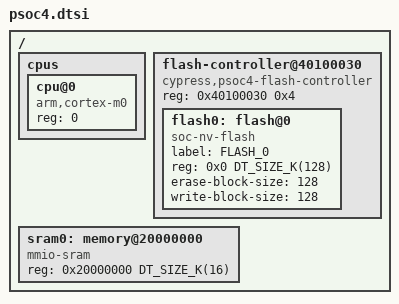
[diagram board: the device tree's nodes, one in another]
/*
 * Copyright (c) 2018, Cypress
 * Copyright (c) 2020-2021, ATL Electronics
 *
 * SPDX-License-Identifier: Apache-2.0
 */

#include <mem.h>
#include <zephyr/dt-bindings/gpio/gpio.h>

/* #include "psoc4-pinctrl.dtsi" */

/ {
	cpus {
		#address-cells = <1>;
		#size-cells = <0>;

		cpu@0 {
			device_type = "cpu";
			compatible = "arm,cortex-m0";
			reg = <0>;
		};
	};

	/*check this*/
	flash-controller@40100030 {
		compatible = "cypress,psoc4-flash-controller";
		reg = <0x40100030 0x4>;

		#address-cells = <1>;
		#size-cells = <1>;

		flash0: flash@0 {
			compatible = "soc-nv-flash";
			label = "FLASH_0";
			reg = <0x0 DT_SIZE_K(128)>;
			erase-block-size = <128>;
			write-block-size = <128>;
		};
	};

	sram0: memory@20000000 {
		compatible = "mmio-sram";
		reg = <0x20000000 DT_SIZE_K(16)>;
	};
};
